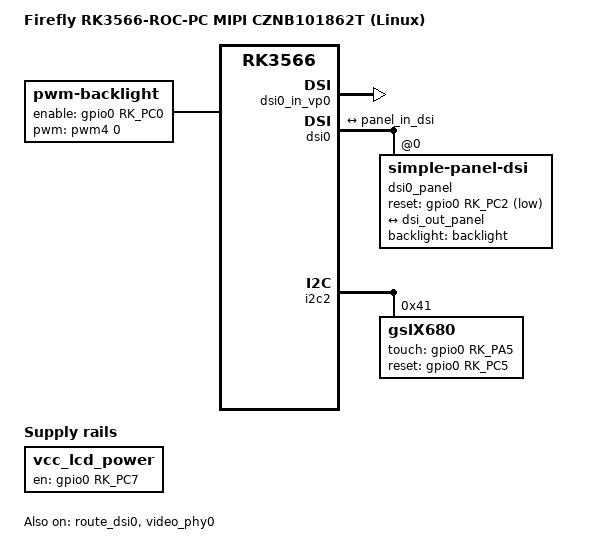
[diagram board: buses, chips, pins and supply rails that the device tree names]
// SPDX-License-Identifier: (GPL-2.0+ OR MIT)
/*
 * Copyright (c) 2020 Rockchip Electronics Co., Ltd.
 *
 */

 /dts-v1/;

#include "rk3566-firefly-roc-pc.dtsi"

/ {
	model = "Firefly RK3566-ROC-PC MIPI CZNB101862T (Linux)";
	compatible = "rockchip,rk3566-firefly-roc-pc", "rockchip,rk3566";

	vcc_lcd_power: vcc-lcd-power-regulator {
		compatible = "regulator-fixed";
		enable-active-high;
		gpio = <&gpio0 RK_PC7 GPIO_ACTIVE_HIGH>;
		pinctrl-names = "default";
		pinctrl-0 = <&vcc_lcd_power_en>;
		regulator-name = "vcc_lcd_power_en";
		regulator-always-on;
	};

	backlight: backlight {
		status = "okay";
		compatible = "pwm-backlight";
		pwms = <&pwm4 0 50000 1>;
		brightness-levels = <
			 95  95  95  95  95  95  95  95
			 95  95  95  95  95  95  95  95
			 95  95  95  95  95  95  95  95
			 95  95  95  95  95  95  95  95
			 95  95  95  95  95  95  95  95
			 95  95  95  95  95  95  95  95
			 95  95  95  95  95  95  95  95
			 95  95  95  95  95  95  95  95
			 95  95  95  95  95  95  95  95
			 95  95  95  95  95  95  95  95
			 95  95  95  95  95  95  95  95
			 88  89  90  91  92  93  94  95
			 96  97  98  99 100 101 102 103
			104 105 106 107 108 109 110 111
			112 113 114 115 116 117 118 119
			120 121 122 123 124 125 126 127
			128 129 130 131 132 133 134 135
			136 137 138 139 140 141 142 143
			144 145 146 147 148 149 150 151
			152 153 154 155 156 157 158 159
			160 161 162 163 164 165 166 167
			168 169 170 171 172 173 174 175
			176 177 178 179 180 181 182 183
			184 185 186 187 188 189 190 191
			192 193 194 195 196 197 198 199
			200 201 202 203 204 205 206 207
			208 209 210 211 212 213 214 215
			216 217 218 219 220 221 222 223
			224 225 226 227 228 229 230 231
			232 233 234 235 236 237 238 239
			240 241 242 243 244 245 246 247
			248 249 250 251 252 253 254 255
		>;
		default-brightness-level = <200>;
		enable-gpios = <&gpio0 RK_PC0 GPIO_ACTIVE_HIGH>;
	};
};

&route_dsi0 {
	status = "okay";
};

&video_phy0 {
	status = "okay";
};

&dsi0_in_vp0 {
    status = "okay";
};

&dsi0_in_vp1 {
    status = "disabled";
};

/*
 * video_phy0 needs to be enabled
 * when dsi0 is enabled
 */
&dsi0 {
	status = "okay";
	//rockchip,lane-rate = <1000>;
	dsi0_panel: panel@0 {
		status = "okay";
		compatible = "simple-panel-dsi";
		reg = <0>;
		backlight = <&backlight>;

		//enable-gpios = <&gpio0 RK_PC7 GPIO_ACTIVE_HIGH>;
		reset-gpios = <&gpio0 RK_PC2 GPIO_ACTIVE_LOW>;
		enable-delay-ms = <35>;
		prepare-delay-ms = <6>;
		reset-delay-ms = <0>;
		init-delay-ms = <20>;
		unprepare-delay-ms = <0>;
		disable-delay-ms = <20>;		
		size,width = <120>;
		size,height = <170>;		
		dsi,flags = <(MIPI_DSI_MODE_VIDEO | MIPI_DSI_MODE_VIDEO_BURST | MIPI_DSI_MODE_LPM | MIPI_DSI_MODE_EOT_PACKET)>;
		dsi,format = <MIPI_DSI_FMT_RGB888>;
		dsi,lanes  = <4>;

		panel-init-sequence = [
			15 00 02 E0 00
			15 00 02 E1 93
			15 00 02 E2 65
			15 00 02 E3 F8

			15 00 02 E0 04
			15 00 02 2D 03		
			15 00 02 E0 00
			15 00 02 80 03		
			//15 00 02 4A 35		
			15 00 02 E0 01
			15 00 02 00 00		
			15 00 02 E0 01
			15 00 02 4B 04
			//15 00 02 4A 35		
			15 00 02 00 00
			15 00 02 01 66
			//15 00 02 03 00		
			//15 00 02 04 6D
			15 00 02 17 00		
			15 00 02 18 AF
			15 00 02 19 01
			15 00 02 1A 00
			15 00 02 1B AF		
			15 00 02 1C 01
			15 00 02 1F 3E		
			15 00 02 20 28
			15 00 02 21 28
			15 00 02 22 7E
			15 00 02 35 05		
			15 00 02 37 09		
			15 00 02 38 04
			15 00 02 39 00
			15 00 02 3A 01
			15 00 02 3C 76
			15 00 02 3D FF
			15 00 02 3E FF
			15 00 02 3F 7F		
			15 00 02 40 06
			15 00 02 41 A0
			15 00 02 42 81
			15 00 02 43 08
			15 00 02 44 0B
			15 00 02 45 28
			//15 00 02 4B 04		
			15 00 02 55 0F
			15 00 02 56 01
			15 00 02 57 69
			15 00 02 58 0A
			15 00 02 59 0A
			15 00 02 5A 29
			15 00 02 5B 15
			//GAMMA
			15 00 02 5D 7C
			15 00 02 5E 66
			15 00 02 5F 57
			15 00 02 60 4A
			15 00 02 61 46
			15 00 02 62 36
			15 00 02 63 3A
			15 00 02 64 23
			15 00 02 65 3A
			15 00 02 66 38
			15 00 02 67 38
			15 00 02 68 55
			15 00 02 69 43
			15 00 02 6A 4A
			15 00 02 6B 3B
			15 00 02 6C 36
			15 00 02 6D 28
			15 00 02 6E 15
			15 00 02 6F 00
			15 00 02 70 7C
			15 00 02 71 66
			15 00 02 72 57
			15 00 02 73 4A
			15 00 02 74 46		
			15 00 02 75 36
			15 00 02 76 3A
			15 00 02 77 23
			15 00 02 78 3A
			15 00 02 79 38
			15 00 02 7A 38
			15 00 02 7B 55
			15 00 02 7C 43
			15 00 02 7D 4A
			15 00 02 7E 3B
			15 00 02 7F 36
			15 00 02 80 28
			15 00 02 81 15
			15 00 02 82 00		
			15 00 02 E0 02		
			15 00 02 00 1E
			15 00 02 01 1E
			15 00 02 02 41
			15 00 02 03 41
			15 00 02 04 43
			15 00 02 05 43
			15 00 02 06 1F
			15 00 02 07 1F
			15 00 02 08 35
			15 00 02 09 1F
			15 00 02 0A 15
			15 00 02 0B 15
			15 00 02 0C 1F
			15 00 02 0D 47
			15 00 02 0E 47
			15 00 02 0F 45
			15 00 02 10 45
			15 00 02 11 4B
			15 00 02 12 4B
			15 00 02 13 49
			15 00 02 14 49
			15 00 02 15 1F		
			15 00 02 16 1E
			15 00 02 17 1E
			15 00 02 18 40
			15 00 02 19 40
			15 00 02 1A 42
			15 00 02 1B 42
			15 00 02 1C 1F
			15 00 02 1D 1F
			15 00 02 1E 35
			15 00 02 1F 1F
			15 00 02 20 15
			15 00 02 21 15
			15 00 02 22 1F
			15 00 02 23 46
			15 00 02 24 46
			15 00 02 25 44
			15 00 02 26 44
			15 00 02 27 4A
			15 00 02 28 4A
			15 00 02 29 48
			15 00 02 2A 48
			15 00 02 2B 1F		
			15 00 02 2C 1F
			15 00 02 2D 1F
			15 00 02 2E 42
			15 00 02 2F 42		
			15 00 02 30 40
			15 00 02 31 40
			15 00 02 32 1E
			15 00 02 33 1E
			15 00 02 34 1F
			15 00 02 35 1F
			15 00 02 36 1E
			15 00 02 37 1E
			15 00 02 38 1F
			15 00 02 39 48
			15 00 02 3A 48
			15 00 02 3B 4A
			15 00 02 3C 4A
			15 00 02 3D 44
			15 00 02 3E 44
			15 00 02 3F 46
			15 00 02 40 46
			15 00 02 41 1F		
			15 00 02 42 1F
			15 00 02 43 1F
			15 00 02 44 43
			15 00 02 45 43
			15 00 02 46 41
			15 00 02 47 41
			15 00 02 48 1E
			15 00 02 49 1E
			15 00 02 4A 1E
			15 00 02 4B 1F
			15 00 02 4C 1E
			15 00 02 4D 1E
			15 00 02 4E 1F
			15 00 02 4F 49
			15 00 02 50 49
			15 00 02 51 4B
			15 00 02 52 4B
			15 00 02 53 45
			15 00 02 54 45
			15 00 02 55 47
			15 00 02 56 47
			15 00 02 57 1F		
			15 00 02 58 40
			15 00 02 59 00
			15 00 02 5A 00
			15 00 02 5B 30
			15 00 02 5C 03
			15 00 02 5D 30
			15 00 02 5E 01
			15 00 02 5F 02
			15 00 02 60 30

			15 00 02 61 01
			15 00 02 62 02
			15 00 02 63 14
			15 00 02 64 6A
			15 00 02 65 05
			15 00 02 66 12
			15 00 02 67 73
			15 00 02 68 05
			15 00 02 69 14
			15 00 02 6A 6A
			15 00 02 6B 08
			15 00 02 6C 00
			15 00 02 6D 00
			15 00 02 6E 00
			15 00 02 6F 88
			15 00 02 70 00
			15 00 02 71 00
			15 00 02 72 06
			15 00 02 73 7B
			15 00 02 74 00
			15 00 02 75 07
			15 00 02 76 00
			15 00 02 77 DD
			15 00 02 78 17
			15 00 02 79 0E
			15 00 02 7A 03
			15 00 02 7B 00
			15 00 02 7C 00
			15 00 02 7D 14
			15 00 02 7E 6A		
			15 00 02 E0 04
			//15 00 02 09 10
			15 00 02 2B 2B
			15 00 02 2E 44
			15 00 02 09 11
			15 00 02 2D 03
			15 00 02 0E 48		
			// 15 00 02 E0 01
			// 15 00 02 0E 01		
			15 00 02 E0 00
			15 00 02 E6 02
			15 00 02 E7 02

			05 78 01 11
			05 05 01 29
			15 00 02 35 00
		];

		panel-exit-sequence = [
			05 05 01 28
			05 78 01 10
		];

		disp_timings0: display-timings {
			native-mode = <&dsi0_timing0>;
			dsi0_timing0: timing0 {
				clock-frequency = <70000000>;//<80000000>;
				hactive = <800>;//<768>;
				vactive = <1280>;
				hsync-len = <10>;   //20, 50,10
				hback-porch = <10>; //50, 56,10
				hfront-porch = <180>;//50, 30,180
				vsync-len = <4>;//4
				vback-porch = <4>;//4
				vfront-porch = <8>;//8
				hsync-active = <0>;
				vsync-active = <0>;
				de-active = <0>;
				pixelclk-active = <0>;
			};
		};

		ports {
			#address-cells = <1>;
			#size-cells = <0>;

			port@0 {
				reg = <0>;
				panel_in_dsi: endpoint {
					remote-endpoint = <&dsi_out_panel>;
				};
			};
		};
	};

	ports {
		#address-cells = <1>;
		#size-cells = <0>;

		port@1 {
			reg = <1>;
			dsi_out_panel: endpoint {
				remote-endpoint = <&panel_in_dsi>;
			};
		};
	};
};

&i2c2 {
	gslx680: gslx680@41 {
		status = "okay";
		compatible = "gslX680";
		reg = <0x41>;
		screen_max_x = <800>;
		screen_max_y = <1280>;
		touch-gpio = <&gpio0 RK_PA5 IRQ_TYPE_LEVEL_LOW>;
		reset-gpio = <&gpio0 RK_PC5 GPIO_ACTIVE_HIGH>;
		flip-x = <1>;
		flip-y = <0>;
		swap-xy = <0>;
		gsl,fw = <1>;
	};
};

&pinctrl {
	lcd {
		vcc_lcd_power_en: vcc-lcd-power-en {
			rockchip,pins = <0 RK_PC7 RK_FUNC_GPIO &pcfg_pull_none>;
		};
	};
};
